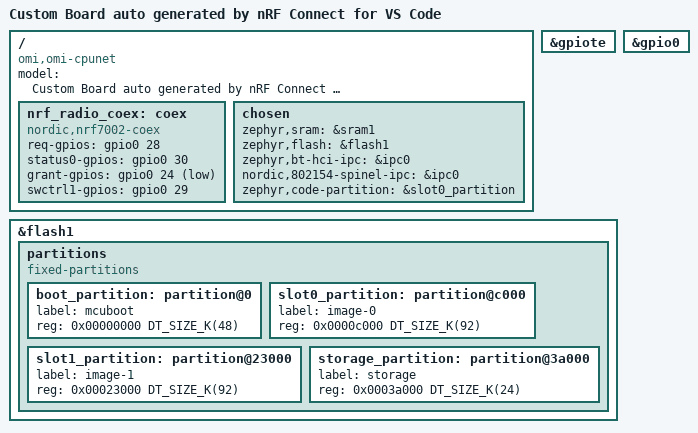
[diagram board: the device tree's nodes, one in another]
/dts-v1/;
#include <nordic/nrf5340_cpunet_qkaa.dtsi>
#include "omi-pinctrl.dtsi"

/ {
	model = "Custom Board auto generated by nRF Connect for VS Code";
	compatible = "omi,omi-cpunet";

	nrf_radio_coex: coex {
		status = "okay";
		compatible = "nordic,nrf7002-coex";

		req-gpios = <&gpio0 28 GPIO_ACTIVE_HIGH>;
		status0-gpios = <&gpio0 30 GPIO_ACTIVE_HIGH>;
		grant-gpios = <&gpio0 24 (GPIO_PULL_DOWN | GPIO_ACTIVE_LOW)>;
		swctrl1-gpios = <&gpio0 29 GPIO_ACTIVE_HIGH>;
	};

	chosen {
		zephyr,sram = &sram1;
		zephyr,flash = &flash1;
		zephyr,bt-hci-ipc = &ipc0;
		nordic,802154-spinel-ipc = &ipc0;
		zephyr,code-partition = &slot0_partition;
	};
};

&gpiote {
	status = "okay";
};

&gpio0 {
	status = "okay";
};

&flash1 {
	partitions {
		compatible = "fixed-partitions";
		#address-cells = <1>;
		#size-cells = <1>;

		boot_partition: partition@0 {
			label = "mcuboot";
			reg = <0x00000000 DT_SIZE_K(48)>;
		};

		slot0_partition: partition@c000 {
			label = "image-0";
			reg = <0x0000c000 DT_SIZE_K(92)>;
		};

		slot1_partition: partition@23000 {
			label = "image-1";
			reg = <0x00023000 DT_SIZE_K(92)>;
		};

		storage_partition: partition@3a000 {
			label = "storage";
			reg = <0x0003a000 DT_SIZE_K(24)>;
		};
	};
};

#include "omi-shared_sram.dtsi"
